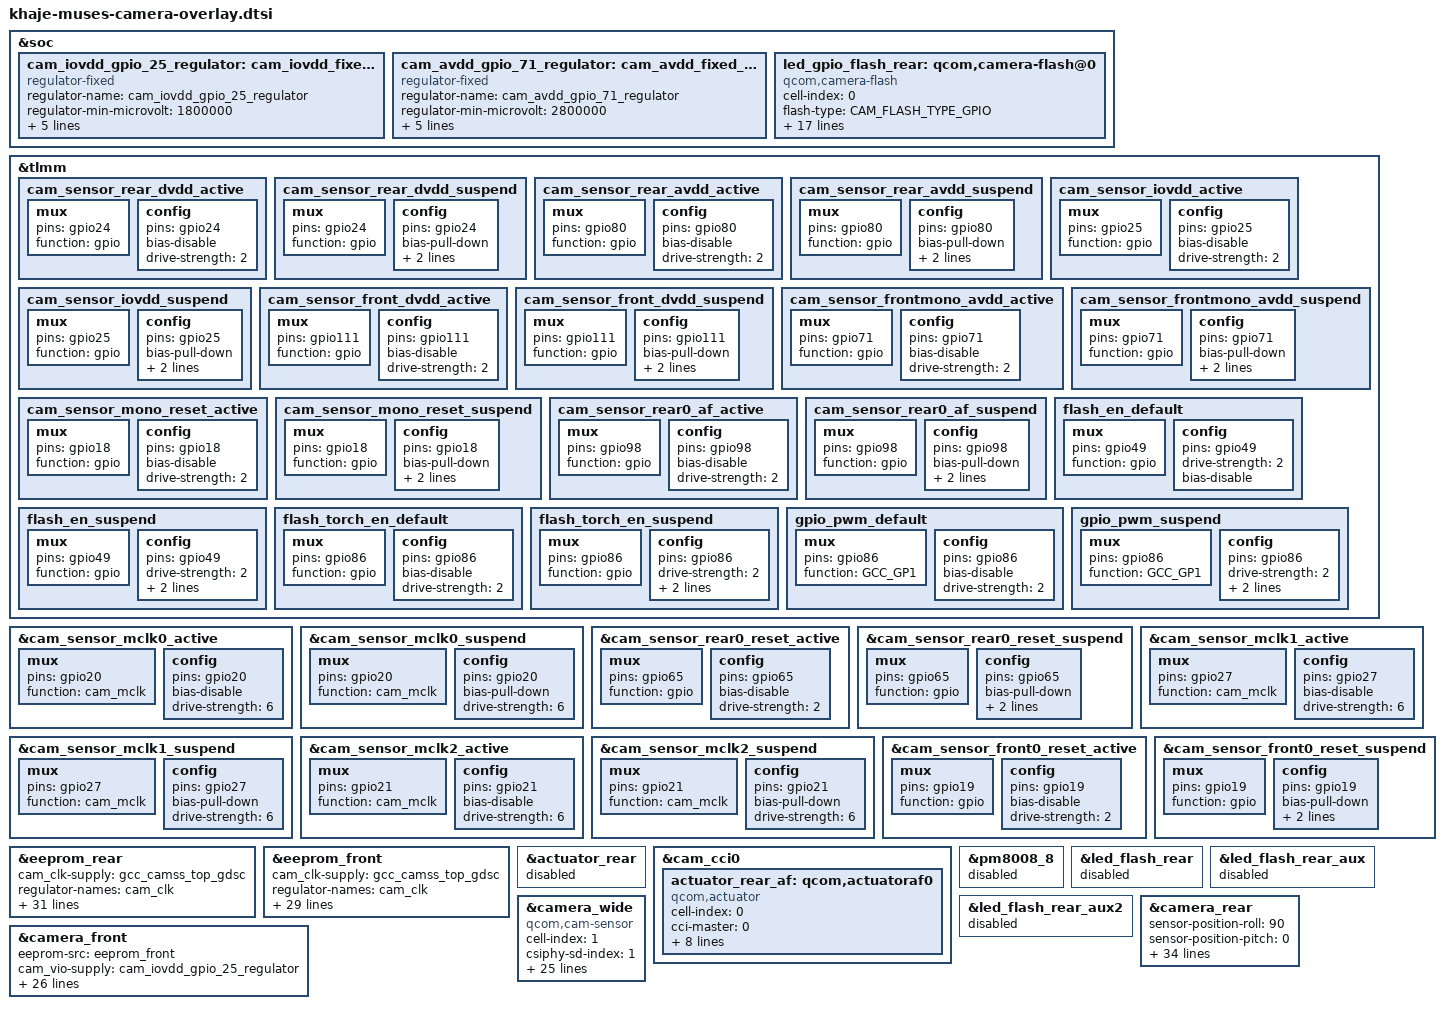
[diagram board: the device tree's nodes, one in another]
//khaje-camera-sensor-qrd.dtsi

&soc {
    cam_iovdd_gpio_25_regulator:cam_iovdd_fixed_regulator {
        compatible = "regulator-fixed";
        regulator-name = "cam_iovdd_gpio_25_regulator";
        regulator-min-microvolt = <1800000>;
        regulator-max-microvolt = <1800000>;
        enable-active-high;
        gpio = <&tlmm 25 0>;
        pinctrl-names = "cam_default","cam_suspend";
        pinctrl-0 = <&cam_sensor_iovdd_active>;
        pinctrl-1 = <&cam_sensor_iovdd_suspend>;
        //vin-supply = <&pm8008_l6>;
    };
    cam_avdd_gpio_71_regulator:cam_avdd_fixed_regulator {
        compatible = "regulator-fixed";
        regulator-name = "cam_avdd_gpio_71_regulator";
        regulator-min-microvolt = <2800000>;
        regulator-max-microvolt = <2800000>;
        enable-active-high;
        gpio = <&tlmm 71 0>;
        pinctrl-names = "cam_default","cam_suspend";
        pinctrl-0 = <&cam_sensor_frontmono_avdd_active>;
        pinctrl-1 = <&cam_sensor_frontmono_avdd_suspend>;
        //vin-supply = <&pm8008_l6>;
    };
};

&tlmm {

    cam_sensor_rear_dvdd_active: cam_sensor_rear_dvdd_active {
        mux {
            pins = "gpio24";
            function = "gpio";
        };
        config {
            pins = "gpio24";
            bias-disable; /* No PULL */
            drive-strength = <2>; /* 2 MA */
        };
    };
    cam_sensor_rear_dvdd_suspend: cam_sensor_rear_dvdd_suspend {
        mux {
            pins = "gpio24";
            function = "gpio";
        };
        config {
            pins = "gpio24";
            bias-pull-down; /* PULL DOWN */
            drive-strength = <2>; /* 2 MA */
            output-low;
        };
    };
    cam_sensor_rear_avdd_active: cam_sensor_rear_avdd_active {
        mux {
            pins = "gpio80";
            function = "gpio";
        };
        config {
            pins = "gpio80";
            bias-disable; /* No PULL */
            drive-strength = <2>; /* 2 MA */
        };
    };
    cam_sensor_rear_avdd_suspend: cam_sensor_rear_avdd_suspend {
        mux {
            pins = "gpio80";
            function = "gpio";
        };
        config {
            pins = "gpio80";
            bias-pull-down; /* PULL DOWN */
            drive-strength = <2>; /* 2 MA */
            output-low;
        };
    };
    cam_sensor_iovdd_active: cam_sensor_iovdd_active {
        mux {
            pins = "gpio25";
            function = "gpio";
        };
        config {
            pins = "gpio25";
            bias-disable; /* No PULL */
            drive-strength = <2>; /* 2 MA */
        };
    };
    cam_sensor_iovdd_suspend: cam_sensor_iovdd_suspend {
        mux {
            pins = "gpio25";
            function = "gpio";
        };
        config {
            pins = "gpio25";
            bias-pull-down; /* PULL DOWN */
            drive-strength = <2>; /* 2 MA */
            output-low;
        };
    };
    cam_sensor_front_dvdd_active: cam_sensor_front_dvdd_active {
        mux {
            pins = "gpio111";
            function = "gpio";
        };
        config {
            pins = "gpio111";
            bias-disable; /* No PULL */
            drive-strength = <2>; /* 2 MA */
        };
    };
    cam_sensor_front_dvdd_suspend: cam_sensor_front_dvdd_suspend {
        mux {
            pins = "gpio111";
            function = "gpio";
        };
        config {
            pins = "gpio111";
            bias-pull-down; /* PULL DOWN */
            drive-strength = <2>; /* 2 MA */
            output-low;
        };
    };
    cam_sensor_frontmono_avdd_active: cam_sensor_frontmono_avdd_active {
        mux {
            pins = "gpio71";
            function = "gpio";
        };
        config {
            pins = "gpio71";
            bias-disable; /* No PULL */
            drive-strength = <2>; /* 2 MA */
        };
    };
    cam_sensor_frontmono_avdd_suspend: cam_sensor_frontmono_avdd_suspend {
        mux {
            pins = "gpio71";
            function = "gpio";
        };
        config {
            pins = "gpio71";
            bias-pull-down; /* PULL DOWN */
            drive-strength = <2>; /* 2 MA */
            output-low;
        };
    };
    cam_sensor_mono_reset_active: cam_sensor_mono_reset_active {
        mux {
            pins = "gpio18";
            function = "gpio";
        };
        config {
            pins = "gpio18";
            bias-disable; /* No PULL */
            drive-strength = <2>; /* 2 MA */
        };
    };
    cam_sensor_mono_reset_suspend: cam_sensor_mono_reset_suspend {
        mux {
            pins = "gpio18";
            function = "gpio";
        };
        config {
            pins = "gpio18";
            bias-pull-down; /* PULL DOWN */
            drive-strength = <2>; /* 2 MA */
            output-low;
        };
    };

    cam_sensor_rear0_af_active: cam_sensor_rear0_af_active {
        mux {
            pins = "gpio98";
            function = "gpio";
        };
        config {
            pins = "gpio98";
            bias-disable; /* No PULL */
            drive-strength = <2>; /* 2 MA */
        };
    };
    cam_sensor_rear0_af_suspend: cam_sensor_rear0_af_suspend {
        mux {
            pins = "gpio98";
            function = "gpio";
        };
        config {
            pins = "gpio98";
            bias-pull-down; /* PULL DOWN */
            drive-strength = <2>; /* 2 MA */
            output-low;
        };
    };

    flash_en_default: flash_en_default {
        mux {
            pins = "gpio49";
            function = "gpio";
        };
        config {
            pins = "gpio49";
            drive-strength = <2>;
            bias-disable; /* No PULL */
        };
    };

    flash_en_suspend: flash_en_suspend {
        mux {
            pins = "gpio49";
            function = "gpio";
        };
        config {
            pins = "gpio49";
            drive-strength = <2>;
            bias-pull-down;
            output-low;
        };
    };
    flash_torch_en_default: flash_torch_en_default {
        mux {
            pins = "gpio86";
            function = "gpio";
        };
        config {
            pins = "gpio86";
            bias-disable; /* No PULL */
            drive-strength = <2>;
        };
    };

    flash_torch_en_suspend: flash_torch_en_suspend {
        mux {
            pins = "gpio86";
            function = "gpio";
        };
        config {
            pins = "gpio86";
            drive-strength = <2>;
            bias-pull-down;
            output-low;
        };
    };

    gpio_pwm_default: gpio_pwm_default {
        mux {
            pins = "gpio86";
            function = "GCC_GP1";
        };

        config {
            pins = "gpio86";
            bias-disable; /* No PULL */
            drive-strength = <2>;
        };
    };

    gpio_pwm_suspend: gpio_pwm_suspend {
        mux {
            pins = "gpio86";
            function = "GCC_GP1";
        };

        config {
            pins = "gpio86";
            drive-strength = <2>;
            bias-pull-down;
            output-low;
        };
    };
};

&cam_sensor_mclk0_active {
    /* MCLK 0*/
    mux {
        pins = "gpio20";
        function = "cam_mclk";
    };

    config {
        pins = "gpio20";
        bias-disable; /* No PULL */
        drive-strength = <6>; /* 2 MA */
    };
};

&cam_sensor_mclk0_suspend {
    /* MCLK 0*/
    mux {
        pins = "gpio20";
        function = "cam_mclk";
    };

    config {
        pins = "gpio20";
        bias-pull-down; /* PULL DOWN */
        drive-strength = <6>; /* 2 MA */
    };
};

&cam_sensor_rear0_reset_active {
    mux {
        pins = "gpio65";
        function = "gpio";
    };
    config {
        pins = "gpio65";
        bias-disable; /* No PULL */
        drive-strength = <2>; /* 2 MA */
    };
};

&cam_sensor_rear0_reset_suspend {
    mux {
        pins = "gpio65";
        function = "gpio";
    };
    config {
        pins = "gpio65";
        bias-pull-down; /* PULL DOWN */
        drive-strength = <2>; /* 2 MA */
        output-low;
    };
};

&cam_sensor_mclk1_active {
    /* MCLK 1*/
    mux {
        pins = "gpio27";
        function = "cam_mclk";
    };

    config {
        pins = "gpio27";
        bias-disable; /* No PULL */
        drive-strength = <6>; /* 2 MA */
    };
};
&cam_sensor_mclk1_suspend {
    /* MCLK 1*/
    mux {
        pins = "gpio27";
        function = "cam_mclk";
    };

    config {
        pins = "gpio27";
        bias-pull-down; /* PULL DOWN */
        drive-strength = <6>; /* 2 MA */
    };
};

&cam_sensor_mclk2_active {
    /* MCLK 0*/
    mux {
        pins = "gpio21";
        function = "cam_mclk";
    };

    config {
        pins = "gpio21";
        bias-disable; /* No PULL */
        drive-strength = <6>; /* 2 MA */
    };
};

&cam_sensor_mclk2_suspend {
    /* MCLK 0*/
    mux {
        pins = "gpio21";
        function = "cam_mclk";
    };

    config {
        pins = "gpio21";
        bias-pull-down; /* PULL DOWN */
        drive-strength = <6>; /* 2 MA */
    };
};

&cam_sensor_front0_reset_active {
    mux {
        pins = "gpio19";
        function = "gpio";
    };
    config {
        pins = "gpio19";
        bias-disable; /* No PULL */
        drive-strength = <2>; /* 2 MA */
    };
};

&cam_sensor_front0_reset_suspend {
    mux {
        pins = "gpio19";
        function = "gpio";
    };
    config {
        pins = "gpio19";
        bias-pull-down; /* PULL DOWN */
        drive-strength = <2>; /* 2 MA */
        output-low;
    };
};

&eeprom_rear {
        //cam_vio-supply = <&cam_iovdd_gpio_25_regulator>;
        cam_clk-supply = <&gcc_camss_top_gdsc>;
        regulator-names = "cam_clk";
        rgltr-cntrl-support;
        pwm-switch;
        rgltr-min-voltage = <0>;
        rgltr-max-voltage = <0>;
        rgltr-load-current = <0>;
        gpio-no-mux = <0>;
        pinctrl-names = "cam_default", "cam_suspend";
        pinctrl-0 = <&cam_sensor_mclk0_active
                     &cam_sensor_rear0_reset_active
                     &cam_sensor_rear_avdd_active
                     &cam_sensor_rear_dvdd_active
                     &cam_sensor_iovdd_active>;
        pinctrl-1 = <&cam_sensor_mclk0_suspend
                     &cam_sensor_rear0_reset_suspend
                     &cam_sensor_rear_avdd_suspend
                     &cam_sensor_rear_dvdd_suspend
                     &cam_sensor_iovdd_suspend>;
        gpios = <&tlmm 20 0>,
                <&tlmm 65 0>,
                <&tlmm 80 0>,
                <&tlmm 24 0>,
                <&tlmm 25 0>;
        gpio-reset = <1>;
        gpio-vana = <2>;
        gpio-vdig = <3>;
        gpio-vio = <4>;
        gpio-req-tbl-num = <0 1 2 3 4>;
        gpio-req-tbl-flags = <1 0 0 0 0>;
        gpio-req-tbl-label = "CAMIF_MCLK0",
                             "CAM_RESET0",
                             "CAM_AVDD00",
                             "CAM_DVDD0",
                             "CAM_DVDDIO0";
        sensor-mode = <0>;
        cci-master = <0>;
        status = "ok";
        clocks = <&gcc GCC_CAMSS_MCLK0_CLK>;
        clock-names = "cam_clk";
        clock-cntl-level = "turbo";
        clock-rates = <24000000>;
};

&eeprom_front {
        //cam_vio-supply = <&cam_iovdd_gpio_25_regulator>;
        cam_clk-supply = <&gcc_camss_top_gdsc>;
        regulator-names = "cam_clk";
        rgltr-cntrl-support;
        pwm-switch;
        rgltr-min-voltage = <0>;
        rgltr-max-voltage = <0>;
        rgltr-load-current = <0>;
        gpio-no-mux = <0>;
        pinctrl-names = "cam_default", "cam_suspend";
        pinctrl-0 = <&cam_sensor_mclk2_active
                     &cam_sensor_front0_reset_active
                     &cam_sensor_frontmono_avdd_active
                     &cam_sensor_front_dvdd_active
                     &cam_sensor_iovdd_active>;
        pinctrl-1 = <&cam_sensor_mclk2_suspend
                     &cam_sensor_front0_reset_suspend
                     &cam_sensor_frontmono_avdd_suspend
                     &cam_sensor_front_dvdd_suspend
                     &cam_sensor_iovdd_suspend>;
        gpios = <&tlmm 21 0>,
                <&tlmm 19 0>,
                <&tlmm 71 0>,
                <&tlmm 111 0>,
                <&tlmm 25 0>;
        gpio-reset = <1>;
        gpio-vana = <2>;
        gpio-vdig = <3>;
        gpio-vio = <4>;

        gpio-req-tbl-num = <0 1 2 3 4>;
        gpio-req-tbl-flags = <1 0 0 0 0>;
        gpio-req-tbl-label = "CAMIF_MCLK1",
                                "CAM_RESET1",
                                "CAM_AVDD1",
                                "CAM_DVDD1",
                                "CAM_DVDDIO1";
        cci-master = <1>;
        clocks = <&gcc GCC_CAMSS_MCLK1_CLK>;
        clock-rates = <24000000>;
};


&actuator_rear {
    status = "disable";
};

&cam_cci0 {
        actuator_rear_af: qcom,actuatoraf0 {
                cell-index = <0>;
                compatible = "qcom,actuator";
                cci-master = <0>;
                gpio-no-mux = <0>;
                pinctrl-names = "cam_default", "cam_suspend";
                pinctrl-0 = <&cam_sensor_rear0_af_active>;
                pinctrl-1 = <&cam_sensor_rear0_af_suspend>;
                gpios = <&tlmm 98 0>;
                gpio-vaf = <0>;
                gpio-req-tbl-num = <0>;
                gpio-req-tbl-flags = <0>;
                gpio-req-tbl-label = "CAM_VAF";
                status = "ok";
        };
};

&soc {
        led_gpio_flash_rear: qcom,camera-flash@0 {
                cell-index = <0>;
                compatible = "qcom,camera-flash";
                flash-type = <CAM_FLASH_TYPE_GPIO>;
                gpio-no-mux = <0>;
                flash-name = "sgm3785";
                pinctrl-names = "cam_default", "cam_suspend","pwm_default","pwm_suspend";
                pinctrl-0 = <&flash_en_default &flash_torch_en_default>;
                pinctrl-1 = <&flash_en_suspend &flash_torch_en_suspend>;
                pinctrl-2 = <&gpio_pwm_default>;
                pinctrl-3 = <&gpio_pwm_suspend>;
                gpios = <&tlmm 49 0>,
                        <&tlmm 86 0>;
                gpio-custom1 = <0>;
                gpio-custom2 = <1>;
                gpio-req-tbl-num = <0 1>;
                gpio-req-tbl-flags = <0 0>;
                gpio-req-tbl-label = "CUSTOM_GPIO1","CUSTOM_GPIO2";
                clocks = <&gcc GCC_GP1_CLK>;
                clock-names = "gpio-pwm-clk";
                clock-cntl-level = "turbo";
                clock-rates = <48000>;
                status = "ok";
        };
};
&pm8008_8 {
	status = "disabled";
};
&led_flash_rear {
	status = "disabled";
};

&led_flash_rear_aux{
    status = "disabled";
};
&led_flash_rear_aux2{
    status = "disabled";
};
&camera_rear {
        sensor-position-roll = <90>;
        sensor-position-pitch = <0>;
        sensor-position-yaw = <180>;
        actuator-src = <&actuator_rear_af>;
        led-flash-src = <&led_gpio_flash_rear>;
        eeprom-src = <&eeprom_rear>;
        cam_vio-supply = <&cam_iovdd_gpio_25_regulator>;
        cam_clk-supply = <&gcc_camss_top_gdsc>;
        regulator-names = "cam_vio","cam_clk";
        rgltr-cntrl-support;
        pwm-switch;
        rgltr-min-voltage = <1800000 0>;
        rgltr-max-voltage = <1800000 0>;
        rgltr-load-current = <120000 0>;
        gpio-no-mux = <0>;
        pinctrl-names = "cam_default", "cam_suspend";
        pinctrl-0 = <&cam_sensor_mclk0_active
                     &cam_sensor_rear0_reset_active
                     &cam_sensor_rear_avdd_active
                     &cam_sensor_rear_dvdd_active>;
        pinctrl-1 = <&cam_sensor_mclk0_suspend
                     &cam_sensor_rear0_reset_suspend
                     &cam_sensor_rear_avdd_suspend
                     &cam_sensor_rear_dvdd_suspend>;

        gpios = <&tlmm 20 0>,
                <&tlmm 65 0>,
                <&tlmm 80 0>,
                <&tlmm 24 0>;
        gpio-reset = <1>;
        gpio-vana = <2>;
        gpio-vdig = <3>;
        gpio-req-tbl-num = <0 1 2 3>;
        gpio-req-tbl-flags = <1 0 0 0>;
        gpio-req-tbl-label = "CAMIF_MCLK0",
                             "CAM_RESET0",
                             "CAM_AVDD00",
                             "CAM_DVDD0";
        sensor-mode = <0>;
        cci-master = <0>;
        status = "ok";
        clocks = <&gcc GCC_CAMSS_MCLK0_CLK>;
        clock-names = "cam_clk";
        clock-cntl-level = "turbo";
        clock-rates = <24000000>;
};
// Mono
&camera_wide {
        cell-index = <1>;
        compatible = "qcom,cam-sensor";
        csiphy-sd-index = <1>;
        sensor-position-roll = <270>;
        sensor-position-pitch = <0>;
        sensor-position-yaw = <180>;
        cam_vio-supply = <&cam_iovdd_gpio_25_regulator>;
        cam_clk-supply = <&gcc_camss_top_gdsc>;
        cam_vana-supply = <&cam_avdd_gpio_71_regulator>;
        regulator-names = "cam_vio","cam_clk","cam_vana";
        rgltr-cntrl-support;
        pwm-switch;
        rgltr-min-voltage = <1800000 0 2800000>;
        rgltr-max-voltage = <1800000 0 2800000>;
        rgltr-load-current = <120000 0 120000>;
        gpio-no-mux = <0>;
        pinctrl-names = "cam_default", "cam_suspend";
        pinctrl-0 = <&cam_sensor_mclk1_active
                     &cam_sensor_mono_reset_active>;
        pinctrl-1 = <&cam_sensor_mclk1_suspend
                     &cam_sensor_mono_reset_suspend>;
        gpios = <&tlmm 27 0>,
                <&tlmm 18 0>;
        gpio-reset = <1>;
        gpio-req-tbl-num = <0 1>;
        gpio-req-tbl-flags = <1 0>;
        gpio-req-tbl-label = "CAMIF_MCLK2",
                                "CAM_RESET2";
        cci-master = <1>;
        clocks = <&gcc GCC_CAMSS_MCLK2_CLK>;
        clock-names = "cam_clk";
        clock-rates = <24000000>;
};

&camera_front {
        eeprom-src = <&eeprom_front>;
        cam_vio-supply = <&cam_iovdd_gpio_25_regulator>;
        cam_clk-supply = <&gcc_camss_top_gdsc>;
        cam_vana-supply = <&cam_avdd_gpio_71_regulator>;
        regulator-names = "cam_vio","cam_clk","cam_vana";
        rgltr-cntrl-support;
        pwm-switch;
        rgltr-min-voltage = <1800000 0 2800000>;
        rgltr-max-voltage = <1800000 0 2800000>;
        rgltr-load-current = <120000 0 120000>;
        gpio-no-mux = <0>;
        pinctrl-names = "cam_default", "cam_suspend";
        pinctrl-0 = <&cam_sensor_mclk2_active
                     &cam_sensor_front0_reset_active
                     &cam_sensor_front_dvdd_active>;
        pinctrl-1 = <&cam_sensor_mclk2_suspend
                     &cam_sensor_front0_reset_suspend
                     &cam_sensor_front_dvdd_suspend>;
        gpios = <&tlmm 21 0>,
                <&tlmm 19 0>,
                <&tlmm 111 0>;
        gpio-reset = <1>;
        gpio-vdig = <2>;
        gpio-custom2 = <0>;
        gpio-req-tbl-num = <0 1 2>;
        gpio-req-tbl-flags = <1 0 0>;
        gpio-req-tbl-label = "CAMIF_MCLK1",
                                "CAM_RESET1",
                                "CAM_DVDD1";
        cci-master = <1>;
        clocks = <&gcc GCC_CAMSS_MCLK1_CLK>;
        clock-rates = <24000000>;
};
